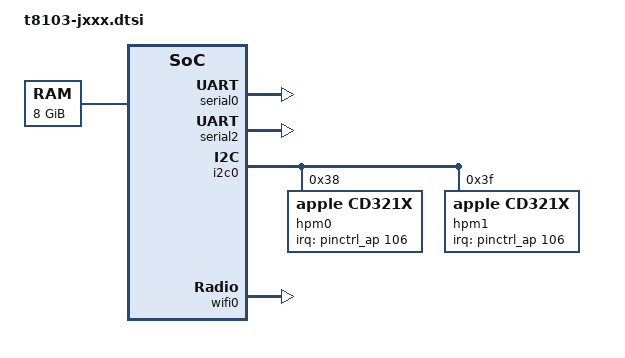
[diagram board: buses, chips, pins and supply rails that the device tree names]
/ {
	aliases {
		bluetooth0 = &bluetooth0;
		serial0 = &serial0;
		serial2 = &serial2;
		wifi0 = &wifi0;
	};
	chosen {
		#address-cells = <2>;
		#size-cells = <2>;
		ranges;
		stdout-path = "serial0";
		framebuffer0: framebuffer@0 {
			compatible = "apple,simple-framebuffer", "simple-framebuffer";
			reg = <0 0 0 0>;  
			status = "disabled";
		};
	};
	memory@800000000 {
		device_type = "memory";
		reg = <0x8 0 0x2 0>;  
	};
};
&serial0 {
	status = "okay";
};
&serial2 {
	status = "okay";
};
&i2c0 {
	hpm0: usb-pd@38 {
		compatible = "apple,cd321x";
		reg = <0x38>;
		interrupt-parent = <&pinctrl_ap>;
		interrupts = <106 IRQ_TYPE_LEVEL_LOW>;
		interrupt-names = "irq";
	};
	hpm1: usb-pd@3f {
		compatible = "apple,cd321x";
		reg = <0x3f>;
		interrupt-parent = <&pinctrl_ap>;
		interrupts = <106 IRQ_TYPE_LEVEL_LOW>;
		interrupt-names = "irq";
	};
};
&port00 {
	bus-range = <1 1>;
	wifi0: network@0,0 {
		compatible = "pci14e4,4425";
		reg = <0x10000 0x0 0x0 0x0 0x0>;
		local-mac-address = [00 00 00 00 00 00];
		apple,antenna-sku = "XX";
	};
	bluetooth0: bluetooth@0,1 {
		compatible = "pci14e4,5f69";
		reg = <0x10100 0x0 0x0 0x0 0x0>;
		local-bd-address = [00 00 00 00 00 00];
	};
};
&nco_clkref {
	clock-frequency = <900000000>;
};
